# CY8C4xxx register map
File version: 0.1
PSoC4A
Registers are 8-bit, read-write, no defined reset value unless marked. A register's access mark holds for its fields unless they carry their own. Offsets are from the block's base; lines under a group give offsets from that group; [hi:lo] are bit positions; {n}, {i} and the like mark numbered series; 'fields as' and 'values as' point back to an identical list; <NAME> marks a mode.

## Memory map
0x0FFFF000 SFLASH size 0x200 — Supervisory Flash Area (Cypress Trim & Wounding Info)
0x10000000 SROM_DATA size 0x1000
0x40000000 CPUSS size 0x10000 — CPU Subsystem
0x40010000 HSIOM size 0x1000 — High-Speed IO-Matrix for PSOC4A
0x40020000 CLK size 0x10000 — Programmable clocks
0x40030000 TST size 0x10000 — Test Subsystem
0x40040000 PRT0 size 0x100 — GPIO Port Registers
0x40040100 PRT1 size 0x100 — GPIO Port Registers
0x40040200 PRT2 size 0x100 — GPIO Port Registers
0x40040300 PRT3 size 0x100 — GPIO Port Registers
0x40040400 PRT4 size 0x100 — GPIO Port Registers
0x40050000 TCPWM size 0x1000 — Quad Timer/Counter/PWM
0x40050100 TCPWM_CNT0 size 0x40 — Timer/Counter/PWM Counter Module
0x40050140 TCPWM_CNT1 size 0x40 — Timer/Counter/PWM Counter Module
0x40050180 TCPWM_CNT2 size 0x40 — Timer/Counter/PWM Counter Module
0x400501C0 TCPWM_CNT3 size 0x40 — Timer/Counter/PWM Counter Module
0x40060000 SCB0 size 0x10000 — Serial Communications Block (SPI/UART/I2C)
0x40070000 SCB1 size 0x10000 — Serial Communications Block (SPI/UART/I2C)
0x40080000 CSD size 0x10000 — Capsense Controller
0x40090000 LCD size 0x10000 — LCD Controller Block
0x400A0000 LPCOMP size 0x10000 — Low Power Comparators
0x400B0000 SRSS size 0x10000 — SRSSv2 Registers (Power, Clock, Reset)
0x400E0000 SPCIF size 0x10000 — Flash Control Interface
0x400F0000 UDB size 0x10000 — Programmable Digital Subsystem
0x400F0000 UDB_W8 size 0x1000 — UDB Working Registers 8-bit mode (1 UDB at a time)
0x400F1000 UDB_W16 size 0x1000 — UDB Working Registers 16-bit mode (2 consecutive UDB's)
0x400F2000 UDB_W32 size 0x1000 — UDB Working Registers 32-bit mode (4 consecutive UDB's)
0x400F3000 UDB_P0_U0 size 0x80 — Single UDB Configuration
0x400F3080 UDB_P0_U1 size 0x80 — Single UDB Configuration
0x400F3100 UDB_P0_ROUTE size 0x100 — Routing Configuration for one UDB Pair
0x400F3200 UDB_P1_U0 size 0x80 — Single UDB Configuration
0x400F3280 UDB_P1_U1 size 0x80 — Single UDB Configuration
0x400F3300 UDB_P1_ROUTE size 0x100 — Routing Configuration for one UDB Pair
0x400F4000 UDB_DSI0 size 0x100 — DSI Configuration (16 DSI)
0x400F4100 UDB_DSI1 size 0x100 — DSI Configuration (16 DSI)
0x400F4200 UDB_DSI2 size 0x100 — DSI Configuration (16 DSI)
0x400F4300 UDB_DSI3 size 0x100 — DSI Configuration (16 DSI)
0x400F5000 UDB_PA0 size 0x10 — Port Adapter Configuration
0x400F5010 UDB_PA1 size 0x10 — Port Adapter Configuration
0x400F5020 UDB_PA2 size 0x10 — Port Adapter Configuration
0x400F5030 UDB_PA3 size 0x10 — Port Adapter Configuration
0x400F6000 UDB_BCTL0 size 0x1000 — UDB Array Bank Control
0x400F7000 UDB_UDBIF size 0x1000 — UDB Subsystem Interface Configuration
0x40100000 CTBM size 0x10000 — Continuous Time Block Mini
0x401A0000 SAR size 0x10000 — SAR ADC with Sequencer
0xE0000000 CM0 size 0x100000 — Cortex-M0 System Bus (ARM PPB Peripherals)
0xF0000000 CoreSightTable_DATA size 0x1000

## HSIOM — High-Speed IO-Matrix for PSOC4A
Base 0x40010000
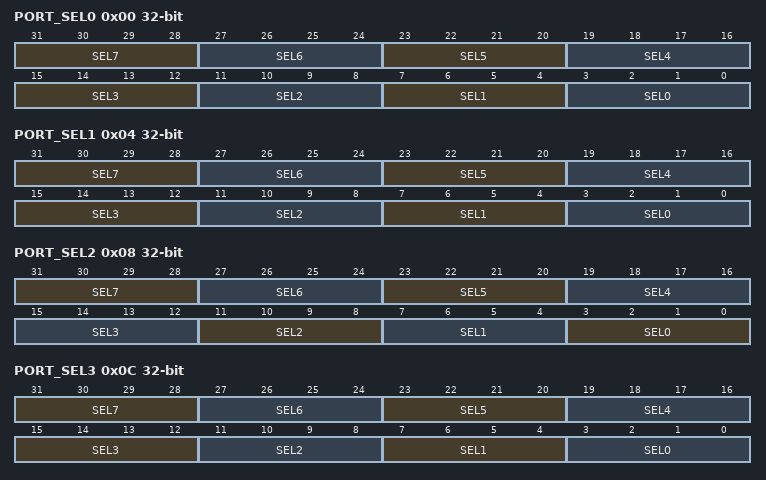
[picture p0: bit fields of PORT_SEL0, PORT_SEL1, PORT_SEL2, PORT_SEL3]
0x00 PORT_SEL0 32-bit — Port 0 control register.
  [31:28] SEL7 — Selects pin 7 source.
    14=WAKEUP; 15=SCB1_SPI_SSEL0
  [27:24] SEL6 — Selects pin 6 source.
    8=EXT_CLK; 15=SCB1_SPI_CLK
  [23:20] SEL5 — Selects pin 5 source.
    9=SCB1_UART_TX; 14=SCB1_I2C_SDA; 15=SCB1_SPI_MISO
  [19:16] SEL4 — Selects pin 4 source.
    9=SCB1_UART_RX; 14=SCB1_I2C_SCL; 15=SCB1_SPI_MOSI
  [15:12] SEL3 — Selects pin 3 source.
    0=COMP2_INN
  [11:8] SEL2 — Selects pin 2 source.
    0=COMP2_INP; 15=SCB0_SPI_SSEL3
  [7:4] SEL1 — Selects pin 1 source.
    0=COMP1_INN; 15=SCB0_SPI_SSEL2
  [3:0] SEL0 — Selects pin 0 source. All of the values given for this field are usable for any pin. Only SARMUX_0 is specific to P0.0.
    0=GPIO; 1=GPIO_DSI; 2=DSI_DSI; 3=DSI_GPIO; 4=CSD_SENSE; 5=CSD_SHIELD; 6=AMUXA; 7=AMUXB; {v}=ACT_{v-8} (v=8..11); 12=LCD_COM; 13=LCD_SEG; 14=DPSLP_0; 15=DPSLP_1; 0=COMP1_INP; 15=SCB0_SPI_SSEL1
0x04 PORT_SEL1 32-bit — Port 1 control register.
  [31:28] SEL7 — Selects pin 7 source.
    0=EXT_VREF
  [27:24] SEL6 — Selects pin 6 source.
  [23:20] SEL5 — Selects pin 5 source.
    0=CTB_OA2_INP
  [19:16] SEL4 — Selects pin 4 source.
    0=CTB_OA2_INN
  [15:12] SEL3 — Selects pin 3 source.
    0=CTB_OA2_OUT; 8=TCPWM3_N
  [11:8] SEL2 — Selects pin 2 source.
    0=CTB_OA1_OUT; 8=TCPWM3_P
  [7:4] SEL1 — Selects pin 1 source.
    0=CTB_OA1_INN; 8=TCPWM2_N
  [3:0] SEL0 — Selects pin 0 source.
    0=CTB_OA1_INP; 8=TCPWM2_P
0x08 PORT_SEL2 32-bit — Port 2 control register.
  [31:28] SEL7 — Selects pin 7 source.
    0=SARMUX_7; 8=TCPWM1_N
  [27:24] SEL6 — Selects pin 6 source.
    0=SARMUX_6; 8=TCPWM1_P
  [23:20] SEL5 — Selects pin 5 source.
    0=SARMUX_5; 8=TCPWM0_N
  [19:16] SEL4 — Selects pin 4 source.
    0=SARMUX_4; 8=TCPWM0_P
  [4n+3:4n] SEL{n} (n=0..3) — Selects pin {n} source.
    0=SARMUX_{n}
0x0C PORT_SEL3 32-bit — Port 3 control register.
  [31:28] SEL7 — Selects pin 7 source.
    8=TCPWM3_N; 14=SWD_CLK
  [27:24] SEL6 — Selects pin 6 source.
    8=TCPWM3_P; 14=SWD_IO; 15=SCB1_SPI_SSEL3
  [23:20] SEL5 — Selects pin 5 source.
    8=TCPWM2_N; 15=SCB1_SPI_SSEL2
  [19:16] SEL4 — Selects pin 4 source.
    8=TCPWM2_P; 15=SCB1_SPI_SSEL1
  [15:12] SEL3 — Selects pin 3 source.
    8=TCPWM1_N; 14=SWD_CLK; 15=SCB1_SPI_SSEL0
  [11:8] SEL2 — Selects pin 2 source.
    8=TCPWM1_P; 14=SWD_IO; 15=SCB1_SPI_CLK
  [7:4] SEL1 — Selects pin 1 source.
    8=TCPWM0_N; 9=SCB1_UART_TX; 14=SCB1_I2C_SDA; 15=SCB1_SPI_MISO
  [3:0] SEL0 — Selects pin 0 source.
    8=TCPWM0_P; 9=SCB1_UART_RX; 14=SCB1_I2C_SCL; 15=SCB1_SPI_MOSI
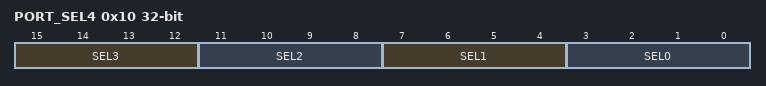
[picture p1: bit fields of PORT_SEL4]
0x10 PORT_SEL4 32-bit — Port 4 control register.
  [15:12] SEL3 — Selects pin 3 source.
    7=CSD_CSHTANK; 7=CSD_CSHTANK_CHRG; 15=SCB0_SPI_SSEL0
  [11:8] SEL2 — Selects pin 2 source.
    6=CSD_CMOD; 7=CSD_CMOD_CHRG; 15=SCB0_SPI_CLK
  [7:4] SEL1 — Selects pin 1 source.
    9=SCB0_UART_TX; 14=SCB0_I2C_SDA; 15=SCB0_SPI_MISO
  [3:0] SEL0 — Selects pin 0 source.
    9=SCB0_UART_RX; 14=SCB0_I2C_SCL; 15=SCB0_SPI_MOSI
